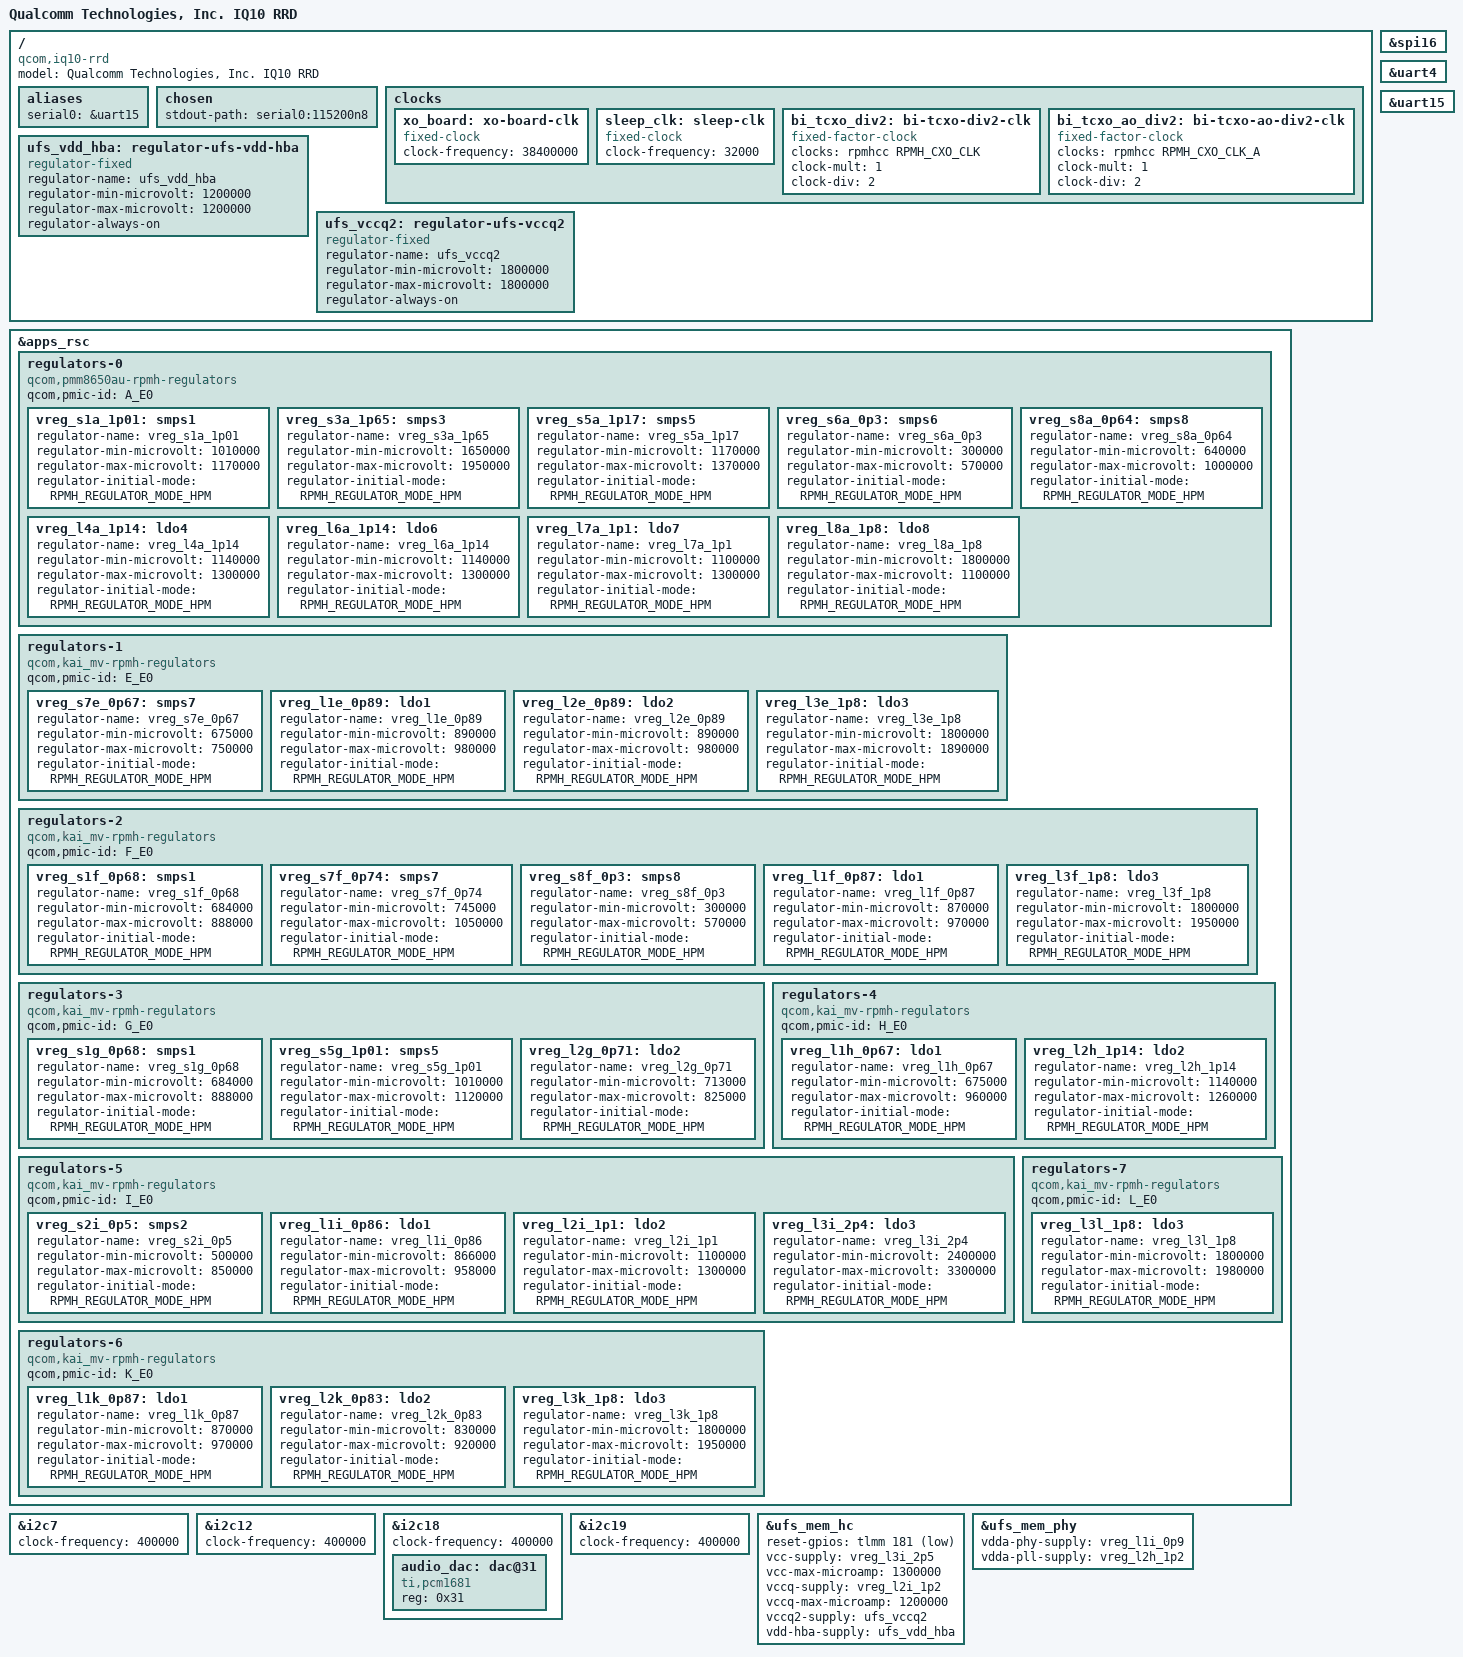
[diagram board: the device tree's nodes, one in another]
// SPDX-License-Identifier: BSD-3-Clause
/*
 * Copyright (c) 2024-2025, Qualcomm Innovation Center, Inc. All rights reserved.
 */

/dts-v1/;

#include <dt-bindings/gpio/gpio.h>
#include <dt-bindings/regulator/qcom,rpmh-regulator.h>

#include "nord-embedded.dtsi"

/ {
	model = "Qualcomm Technologies, Inc. IQ10 RRD";
	compatible = "qcom,iq10-rrd", "qcom,nord";

	aliases {
		serial0 = &uart15;
	};

	chosen {
		stdout-path = "serial0:115200n8";
	};

	clocks {
		xo_board: xo-board-clk {
			compatible = "fixed-clock";
			clock-frequency = <38400000>;
			#clock-cells = <0>;
		};

		sleep_clk: sleep-clk {
			compatible = "fixed-clock";
			clock-frequency = <32000>;
			#clock-cells = <0>;
		};

		bi_tcxo_div2: bi-tcxo-div2-clk {
			compatible = "fixed-factor-clock";
			#clock-cells = <0>;
			clocks = <&rpmhcc RPMH_CXO_CLK>;
			clock-mult = <1>;
			clock-div = <2>;
		};

		bi_tcxo_ao_div2: bi-tcxo-ao-div2-clk {
			compatible = "fixed-factor-clock";
			#clock-cells = <0>;
			clocks = <&rpmhcc RPMH_CXO_CLK_A>;
			clock-mult = <1>;
			clock-div = <2>;
		};
	};

	ufs_vdd_hba: regulator-ufs-vdd-hba {
		compatible = "regulator-fixed";
		regulator-name = "ufs_vdd_hba";
		regulator-min-microvolt = <1200000>;
		regulator-max-microvolt = <1200000>;
		regulator-always-on;
	};

	ufs_vccq2: regulator-ufs-vccq2 {
		compatible = "regulator-fixed";
		regulator-name = "ufs_vccq2";
		regulator-min-microvolt = <1800000>;
		regulator-max-microvolt = <1800000>;
		regulator-always-on;
	};
};

&apps_rsc {
	regulators-0 {
		compatible = "qcom,pmm8650au-rpmh-regulators";
		qcom,pmic-id = "A_E0";

		vreg_s1a_1p01: smps1 {
			regulator-name = "vreg_s1a_1p01";
			regulator-min-microvolt = <1010000>;
			regulator-max-microvolt = <1170000>;
			regulator-initial-mode = <RPMH_REGULATOR_MODE_HPM>;
		};

		vreg_s3a_1p65: smps3 {
			regulator-name = "vreg_s3a_1p65";
			regulator-min-microvolt = <1650000>;
			regulator-max-microvolt = <1950000>;
			regulator-initial-mode = <RPMH_REGULATOR_MODE_HPM>;
		};

		vreg_s5a_1p17: smps5 {
			regulator-name = "vreg_s5a_1p17";
			regulator-min-microvolt = <1170000>;
			regulator-max-microvolt = <1370000>;
			regulator-initial-mode = <RPMH_REGULATOR_MODE_HPM>;
		};

		vreg_s6a_0p3: smps6 {
			regulator-name = "vreg_s6a_0p3";
			regulator-min-microvolt = <300000>;
			regulator-max-microvolt = <570000>;
			regulator-initial-mode = <RPMH_REGULATOR_MODE_HPM>;
		};

		vreg_s8a_0p64: smps8 {
			regulator-name = "vreg_s8a_0p64";
			regulator-min-microvolt = <640000>;
			regulator-max-microvolt = <1000000>;
			regulator-initial-mode = <RPMH_REGULATOR_MODE_HPM>;
		};

		vreg_l4a_1p14: ldo4 {
			regulator-name = "vreg_l4a_1p14";
			regulator-min-microvolt = <1140000>;
			regulator-max-microvolt = <1300000>;
			regulator-initial-mode = <RPMH_REGULATOR_MODE_HPM>;
		};

		vreg_l6a_1p14: ldo6 {
			regulator-name = "vreg_l6a_1p14";
			regulator-min-microvolt = <1140000>;
			regulator-max-microvolt = <1300000>;
			regulator-initial-mode = <RPMH_REGULATOR_MODE_HPM>;
		};

		vreg_l7a_1p1: ldo7 {
			regulator-name = "vreg_l7a_1p1";
			regulator-min-microvolt = <1100000>;
			regulator-max-microvolt = <1300000>;
			regulator-initial-mode = <RPMH_REGULATOR_MODE_HPM>;
		};

		vreg_l8a_1p8: ldo8 {
			regulator-name = "vreg_l8a_1p8";
			regulator-min-microvolt = <1800000>;
			regulator-max-microvolt = <1100000>;
			regulator-initial-mode = <RPMH_REGULATOR_MODE_HPM>;
		};
	};

	regulators-1 {
		compatible = "qcom,kai_mv-rpmh-regulators";
		qcom,pmic-id = "E_E0";

		vreg_s7e_0p67: smps7 {
			regulator-name = "vreg_s7e_0p67";
			regulator-min-microvolt = <675000>;
			regulator-max-microvolt = <750000>;
			regulator-initial-mode = <RPMH_REGULATOR_MODE_HPM>;
		};

		vreg_l1e_0p89: ldo1 {
			regulator-name = "vreg_l1e_0p89";
			regulator-min-microvolt = <890000>;
			regulator-max-microvolt = <980000>;
			regulator-initial-mode = <RPMH_REGULATOR_MODE_HPM>;
		};

		vreg_l2e_0p89: ldo2 {
			regulator-name = "vreg_l2e_0p89";
			regulator-min-microvolt = <890000>;
			regulator-max-microvolt = <980000>;
			regulator-initial-mode = <RPMH_REGULATOR_MODE_HPM>;
		};

		vreg_l3e_1p8: ldo3 {
			regulator-name = "vreg_l3e_1p8";
			regulator-min-microvolt = <1800000>;
			regulator-max-microvolt = <1890000>;
			regulator-initial-mode = <RPMH_REGULATOR_MODE_HPM>;
		};
	};

	regulators-2 {
		compatible = "qcom,kai_mv-rpmh-regulators";
		qcom,pmic-id = "F_E0";

		vreg_s1f_0p68: smps1 {
			regulator-name = "vreg_s1f_0p68";
			regulator-min-microvolt = <684000>;
			regulator-max-microvolt = <888000>;
			regulator-initial-mode = <RPMH_REGULATOR_MODE_HPM>;
		};

		vreg_s7f_0p74: smps7 {
			regulator-name = "vreg_s7f_0p74";
			regulator-min-microvolt = <745000>;
			regulator-max-microvolt = <1050000>;
			regulator-initial-mode = <RPMH_REGULATOR_MODE_HPM>;
		};

		vreg_s8f_0p3: smps8 {
			regulator-name = "vreg_s8f_0p3";
			regulator-min-microvolt = <300000>;
			regulator-max-microvolt = <570000>;
			regulator-initial-mode = <RPMH_REGULATOR_MODE_HPM>;
		};

		vreg_l1f_0p87: ldo1 {
			regulator-name = "vreg_l1f_0p87";
			regulator-min-microvolt = <870000>;
			regulator-max-microvolt = <970000>;
			regulator-initial-mode = <RPMH_REGULATOR_MODE_HPM>;
		};

		vreg_l3f_1p8: ldo3 {
			regulator-name = "vreg_l3f_1p8";
			regulator-min-microvolt = <1800000>;
			regulator-max-microvolt = <1950000>;
			regulator-initial-mode = <RPMH_REGULATOR_MODE_HPM>;
		};
	};

	regulators-3 {
		compatible = "qcom,kai_mv-rpmh-regulators";
		qcom,pmic-id = "G_E0";

		vreg_s1g_0p68: smps1 {
			regulator-name = "vreg_s1g_0p68";
			regulator-min-microvolt = <684000>;
			regulator-max-microvolt = <888000>;
			regulator-initial-mode = <RPMH_REGULATOR_MODE_HPM>;
		};

		vreg_s5g_1p01: smps5 {
			regulator-name = "vreg_s5g_1p01";
			regulator-min-microvolt = <1010000>;
			regulator-max-microvolt = <1120000>;
			regulator-initial-mode = <RPMH_REGULATOR_MODE_HPM>;
		};

		vreg_l2g_0p71: ldo2 {
			regulator-name = "vreg_l2g_0p71";
			regulator-min-microvolt = <713000>;
			regulator-max-microvolt = <825000>;
			regulator-initial-mode = <RPMH_REGULATOR_MODE_HPM>;
		};
	};

	regulators-4 {
		compatible = "qcom,kai_mv-rpmh-regulators";
		qcom,pmic-id = "H_E0";

		vreg_l1h_0p67: ldo1 {
			regulator-name = "vreg_l1h_0p67";
			regulator-min-microvolt = <675000>;
			regulator-max-microvolt = <960000>;
			regulator-initial-mode = <RPMH_REGULATOR_MODE_HPM>;
		};

		vreg_l2h_1p14: ldo2 {
			regulator-name = "vreg_l2h_1p14";
			regulator-min-microvolt = <1140000>;
			regulator-max-microvolt = <1260000>;
			regulator-initial-mode = <RPMH_REGULATOR_MODE_HPM>;
		};
	};

	regulators-5 {
		compatible = "qcom,kai_mv-rpmh-regulators";
		qcom,pmic-id = "I_E0";

		vreg_s2i_0p5: smps2 {
			regulator-name = "vreg_s2i_0p5";
			regulator-min-microvolt = <500000>;
			regulator-max-microvolt = <850000>;
			regulator-initial-mode = <RPMH_REGULATOR_MODE_HPM>;
		};

		vreg_l1i_0p86: ldo1 {
			regulator-name = "vreg_l1i_0p86";
			regulator-min-microvolt = <866000>;
			regulator-max-microvolt = <958000>;
			regulator-initial-mode = <RPMH_REGULATOR_MODE_HPM>;
		};

		vreg_l2i_1p1: ldo2 {
			regulator-name = "vreg_l2i_1p1";
			regulator-min-microvolt = <1100000>;
			regulator-max-microvolt = <1300000>;
			regulator-initial-mode = <RPMH_REGULATOR_MODE_HPM>;
		};

		vreg_l3i_2p4: ldo3 {
			regulator-name = "vreg_l3i_2p4";
			regulator-min-microvolt = <2400000>;
			regulator-max-microvolt = <3300000>;
			regulator-initial-mode = <RPMH_REGULATOR_MODE_HPM>;
		};
	};

	regulators-6 {
		compatible = "qcom,kai_mv-rpmh-regulators";
		qcom,pmic-id = "K_E0";

		vreg_l1k_0p87: ldo1 {
			regulator-name = "vreg_l1k_0p87";
			regulator-min-microvolt = <870000>;
			regulator-max-microvolt = <970000>;
			regulator-initial-mode = <RPMH_REGULATOR_MODE_HPM>;
		};

		vreg_l2k_0p83: ldo2 {
			regulator-name = "vreg_l2k_0p83";
			regulator-min-microvolt = <830000>;
			regulator-max-microvolt = <920000>;
			regulator-initial-mode = <RPMH_REGULATOR_MODE_HPM>;
		};

		vreg_l3k_1p8: ldo3 {
			regulator-name = "vreg_l3k_1p8";
			regulator-min-microvolt = <1800000>;
			regulator-max-microvolt = <1950000>;
			regulator-initial-mode = <RPMH_REGULATOR_MODE_HPM>;
		};
	};

	regulators-7 {
		compatible = "qcom,kai_mv-rpmh-regulators";
		qcom,pmic-id = "L_E0";

		vreg_l3l_1p8: ldo3 {
			regulator-name = "vreg_l3l_1p8";
			regulator-min-microvolt = <1800000>;
			regulator-max-microvolt = <1980000>;
			regulator-initial-mode = <RPMH_REGULATOR_MODE_HPM>;
		};
	};
};

&i2c7 {
	clock-frequency = <400000>;
	status = "okay";
};

&i2c12 {
	clock-frequency = <400000>;
	status = "okay";
};

&i2c18 {
	clock-frequency = <400000>;
	status = "okay";

	audio_dac: dac@31 {
		compatible = "ti,pcm1681";
		reg = <0x31>;

		#sound-dai-cells = <0>;
	};
};

&i2c19 {
	clock-frequency = <400000>;
	status = "okay";
};

&spi16 {
	status = "okay";
};

&uart4 {
	status = "okay";
};

&uart15 {
	status = "okay";
};

&ufs_mem_hc {
	reset-gpios = <&tlmm 181 GPIO_ACTIVE_LOW>;

	vcc-supply = <&vreg_l3i_2p5>;
	vcc-max-microamp = <1300000>;
	vccq-supply = <&vreg_l2i_1p2>;
	vccq-max-microamp = <1200000>;
	vccq2-supply = <&ufs_vccq2>;
	vdd-hba-supply = <&ufs_vdd_hba>;
	status = "okay";
};

&ufs_mem_phy {
	vdda-phy-supply = <&vreg_l1i_0p9>;
	vdda-pll-supply = <&vreg_l2h_1p2>;
	status = "okay";
};
